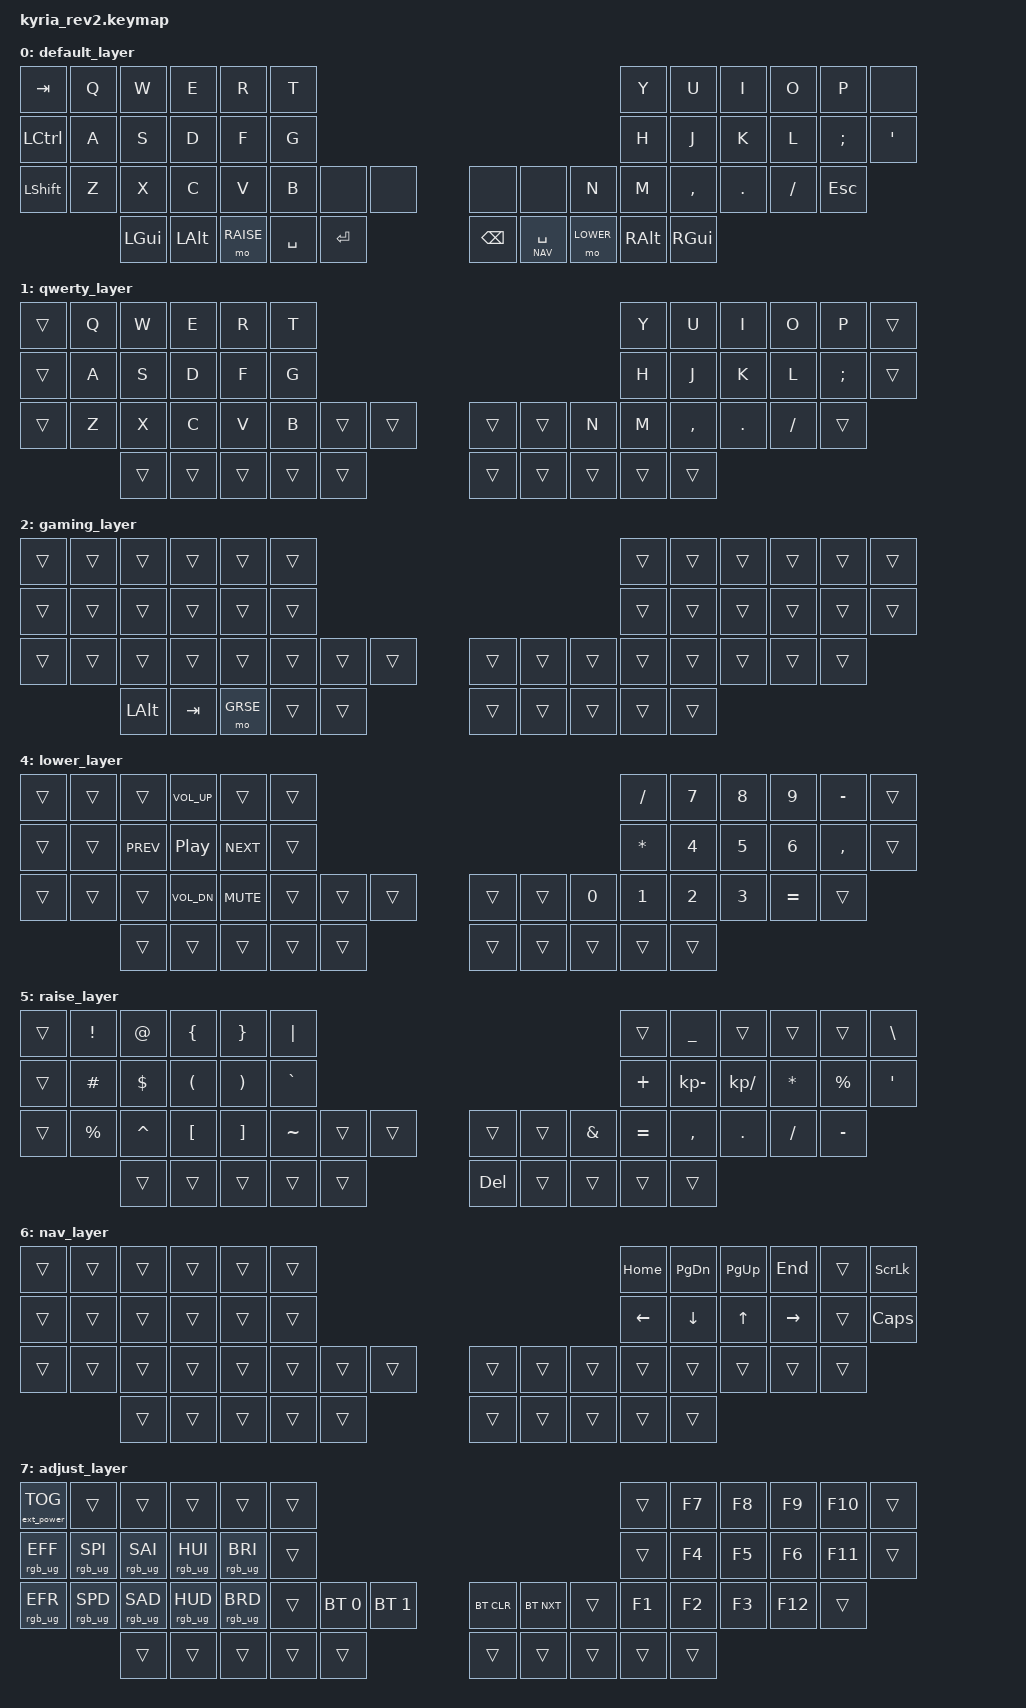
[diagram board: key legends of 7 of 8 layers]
/*
 * Copyright (c) 2020 The ZMK Contributors
 *
 * SPDX-License-Identifier: MIT
 */

#include <behaviors.dtsi>
#include <dt-bindings/zmk/bt.h>
#include <dt-bindings/zmk/keys.h>
/*
 * Temporarily here because nice nano v2 spi is not defined on ZMk Yet
 * Source: https://github.com/zmkfirmware/zmk/blob/main/app/boards/shields/reviung41/boards/nice_nano.overlay
 * GitHub Issue: https://github.com/zmkfirmware/zmk/issues/885
 */


#define QWERTY 0
#define QWERTY2  1
#define GAME    2
#define GRSE    3 // A special raise layer for main-half gaming.
#define LOWER   4
#define RAISE   5
#define NAV     6
#define ADJUST  7

/ {
    conditional_layers {
        compatible = "zmk,conditional-layers";
        tri_layer_1 {
            if-layers = <RAISE LOWER>;
            then-layer = <ADJUST>;
        };

		// Multiple conditional layers targeting the same then-layer is currently bugged.
		// https://github.com/zmkfirmware/zmk/pull/1084
		//tri_layer_2 {
        //    if-layers = <GRSE LOWER>;
        //    then-layer = <ADJUST>;
        //};
    };
};

/ {
    chosen {
      zmk,battery = &vbatt;
    };

    vbatt: vbatt {
        compatible = "zmk,battery-nrf-vddh";
        label = "VBATT";
    };
}

/ {
	keymap {
		compatible = "zmk,keymap";

		default_layer {
// ---------------------------------------------------------------------------------------------------------------------------------
// |  TAB  |  Q   |  W   |  E   |  R   |  T   |                                       |   Y   |   U   |   I   |   O   |   P   |   ENC   |
// |  CTRL |  A   |  S   |  D   |  F   |  G   |                                       |   H   |   J   |   K   |   L   |   ;   |   '   |
// | SHIFT |  Z   |  X   |  C   |  V   |  B   |       |      |         |      | _____ |   N   |   M   |   ,   |   .   |   /   | ESC   |
//                       | GUI  | ALT  | RSE  | SPACE | RET  |         | BSPC | SPACE |  LWR  | R-ALT |  GUI  |
//                                                                              /NAV
			bindings = <
	&kp TAB   &kp Q &kp W &kp E &kp R &kp T                                                      &kp Y     &kp U    &kp I     &kp O   &kp P     &none
	&kp LCTRL &kp A &kp S &kp D &kp F &kp G                                                      &kp H     &kp J    &kp K     &kp L   &kp SEMI    &kp SQT
	&kp LSHFT &kp Z &kp X &kp C &kp V &kp B    	 &none &none              &none &none        &kp N     &kp M    &kp COMMA &kp DOT &kp FSLH &kp ESC
	                &kp LGUI &kp LALT &mo RAISE &kp SPACE &kp RET        &kp BSPC  &lt NAV SPACE &mo LOWER &kp RALT &kp RGUI
			>;

			sensor-bindings = <&inc_dec_kp C_VOL_DN C_VOL_UP>;
		};

		qwerty_layer {
// ---------------------------------------------------------------------------------------------------------------------------------
// | ____ |   Q  |  W   |  E   |  R   |  T   |                                             |  Y   |  U   |  I   |  O   |  P   | ____ |
// | ____ |   A  |  S   |  D   |  F   |  G   |                                             |  H   |  J   |  K   |  L   |  ;   | ____ |
// | ____ |   Z  |  X   |  C   |  V   |  B   | ____ | ____ |                 | ____ | ____ |  N   |  M   |  ,   |  .   |  /   | ____ |
//                      | ____ | ____ | ____ | ____ | ____ |                 | ____ | ____ | ____ | ____ | ____ |
			bindings = <
		
	&trans  &kp Q &kp W &kp E  &kp R  &kp T                                    &kp Y  &kp U  &kp I     &kp O   &kp P    &trans
	&trans  &kp A &kp S &kp D  &kp F  &kp G                                    &kp H  &kp J  &kp K     &kp L   &kp SEMI &trans
	&trans  &kp Z &kp X &kp C  &kp V  &kp B  &trans &trans       &trans &trans &kp N  &kp M  &kp COMMA &kp DOT &kp FSLH &trans
	                    &trans &trans &trans &trans &trans       &trans &trans &trans &trans &trans
			>;

			sensor-bindings = <&inc_dec_kp C_VOL_DN C_VOL_UP>;
		};

		gaming_layer {
// --------------------------------------------------------------------------------------------------------------------------------
// | ____ | ____ | ____ | ____ | ____ | ____ |                                             | ____ | ____ | ____ | ____ | ____ | ____ |
// | ____ | ____ | ____ | ____ | ____ | ____ |                                             | ____ | ____ | ____ | ____ | ____ | ____ |
// | ____ | ____ | ____ | ____ | ____ | ____ | ____ | ____ |                 | ____ | ____ | ____ | ____ | ____ | ____ | ____ | ____ |
//                      | LALT | TAB  | GRSE | ____ | ____ |                 | ____ | ____ | ____ | ____ | ____ |
			bindings = <

	&trans &trans &trans &trans   &trans  &trans                                     &trans &trans &trans &trans &trans &trans
	&trans &trans &trans &trans   &trans  &trans                                     &trans &trans &trans &trans &trans &trans
	&trans &trans &trans &trans   &trans  &trans   &trans &trans       &trans &trans &trans &trans &trans &trans &trans &trans
	                     &kp LALT &kp TAB &mo GRSE &trans &trans       &trans &trans &trans &trans &trans
			>;

			sensor-bindings = <&inc_dec_kp C_VOL_DN C_VOL_UP>;
		};
		
		gaming_raise_layer {
// --------------------------------------------------------------------------------------------------------------------------------
// | F1   |  1   |  2   |  3   |  4   |  5   |                                             | ____ | ____ | ____ | ____ | ____ | ____ |
// | ____ | ____ | ____ | ____ | ____ | ____ |                                             | ____ | ____ | ____ | ____ | ____ | ____ |
// | ____ | ____ | ____ | ____ | ____ | ____ | ____ | ____ |                 | ____ | ____ | ____ | ____ | ____ | ____ | ____ | ____ |
//                      | ____ | ____ | ____ | ____ | ____ |                 | ____ | ____ | ____ | ____ | ____ |
			bindings = <

	&kp F1 &kp N1 &kp N2 &kp N3 &kp N4 &kp N5                                   &trans &trans &trans &trans &trans &trans
	&trans &trans &trans &trans &trans &trans                                   &trans &trans &trans &trans &trans &trans
	&trans &trans &trans &trans &trans &trans                                   &trans &trans &trans &trans &trans &trans
	                     &trans &trans &trans &trans &trans       &trans &trans &trans &trans &trans
			>;

			sensor-bindings = <&inc_dec_kp C_VOL_DN C_VOL_UP>;
		};
		

		lower_layer {
// ---------------------------------------------------------------------------------------------------------------------------------
// | ____ | ____ | ____ | VUP  | ____ | ____ |                                             | / ?  | 7 &  | 8 *  | 9 (  |  - _ | ____ |
// | ____ | ____ | PREV | PLAY | NEXT | ____ |                                             | *    | 4 $  | 5 %  | 6 ^  |  , < | ____ |
// | ____ | ____ | ____ | VDWN | MUTE | ____ | ____ | ____ |                 | ____ | ____ | 0 )  | 1 !  | 2 @  | 3 #  |  = + | ____ |
//                      | ____ | ____ | ____ | ____ | ____ |                 | ____ | ____ | ____ | ____ | ____ |
			bindings = <
	&trans  &trans &trans     &kp C_VOL_UP &trans     &trans                                        &kp FSLH &kp N7 &kp N8 &kp N9 &kp MINUS &trans
	&trans  &trans &kp C_PREV &kp C_PP     &kp C_NEXT &trans                                        &kp STAR &kp N4 &kp N5 &kp N6 &kp COMMA &trans
	&trans  &trans &trans     &kp C_VOL_DN &kp C_MUTE &trans     &trans &trans       &trans  &trans &kp N0   &kp N1 &kp N2 &kp N3 &kp EQUAL &trans
	                          &trans       &trans     &trans     &trans &trans       &trans  &trans &trans   &trans &trans
			>;

			sensor-bindings = <&inc_dec_kp C_VOL_DN C_VOL_UP>;
		};
	
		raise_layer {
// ---------------------------------------------------------------------------------------------------------------------------------
// | ____ |  !   |  @   |  {   |  }   |  |   |                                             | ____ |  _   | ____ | ____ | ____ |  \   |
// | ____ |  #   |  $   |  (   |  )   |  `   |                                             |  +   |  -   |  /   |  *   |  %   | ' "  |
// | ____ |  %   |  ^   |  [   |  ]   |  ~   | ____ | ____ |                 | ____ | ____ |  &   |  =   |  ,   |  .   | / ?  | - _  |
//                      | ____ | ____ | ____ | ____ | ____ |                 | ____ | ____ | ____ | ____ | ____ |
			bindings = <
	&trans  &kp EXCL  &kp AT    &kp LBRC &kp RBRC &kp PIPE                                     &trans     &kp UNDER    &trans       &trans     &trans    &kp BSLH
	&trans  &kp HASH  &kp DLLR  &kp LPAR &kp RPAR &kp GRAVE                                    &kp PLUS   &kp KP_MINUS &kp KP_SLASH &kp STAR   &kp PRCNT &kp SQT
	&trans  &kp PRCNT &kp CARET &kp LBKT &kp RBKT &kp TILDE &trans &trans       &trans  &trans &kp AMPS   &kp EQUAL    &kp COMMA    &kp DOT    &kp FSLH  &kp MINUS
	                            &trans   &trans   &trans    &trans &trans       &kp DEL &trans &trans     &trans       &trans
			>;

			sensor-bindings = <&inc_dec_kp C_VOL_DN C_VOL_UP>;
		};

		nav_layer {
// ---------------------------------------------------------------------------------------------------------------------------------
// | ____ | ____ | ____ | ____ | ____ | ____ |                                             | Home | PgDn | PgUp | End  | ____ | Slck |
// | ____ | ____ | ____ | ____ | ____ | ____ |                                             | Left | Down |  Up  | Right| ____ | Cclk |
// | ____ | ____ | ____ | ____ | ____ | ____ | ____ | ____ |                 | ____ | ____ | ____ | ____ | ____ | ____ | ____ | ____ |
//                      | ____ | ____ | ____ | ____ | ____ |                 | ____ | ____ | ____ | ____ | ____ |
			bindings = <
	&trans &trans &trans &trans &trans &trans                                    &kp HOME  &kp PG_DN &kp PG_UP &kp END   &trans &kp SLCK
	&trans &trans &trans &trans &trans &trans                                    &kp LEFT  &kp DOWN  &kp UP    &kp RIGHT &trans &kp CLCK
	&trans &trans &trans &trans &trans &trans &trans &trans       &trans &trans  &trans    &trans    &trans    &trans    &trans &trans
	                     &trans &trans &trans &trans &trans       &trans &trans  &trans    &trans    &trans
			>;

			sensor-bindings = <&inc_dec_kp C_VOL_DN C_VOL_UP>;
		};

		adjust_layer {
// ---------------------------------------------------------------------------------------------------------------------------------
// | VCC  | ____ | ____ | ____ | ____ | ____ |                                             | ____ |  F7  |  F8  |  F9  | F10  | ____ |
// | EFF  | SPI  | SAI  | HUI  | VAI  | ____ |                                             | ____ |  F4  |  F5  |  F6  | F11  | ____ |
// | EFR  | SPD  | SAD  | HUD  | VAD  | ____ | BLS0 | BLS1 |                 | BCLR | BNXT | ____ |  F1  |  F2  |  F3  | F12  | ____ |
//                      | ____ | ____ | ____ | ____ | ____ |                 | ____ | ____ | ____ | ____ | ____ |
			bindings = <
	&ext_power EP_TOG &trans           &trans            &trans          &trans          &trans                                                        &trans &kp F7 &kp F8 &kp F9 &kp F10 &trans
	&rgb_ug RGB_EFF   &rgb_ug RGB_SPI  &rgb_ug RGB_SAI   &rgb_ug RGB_HUI &rgb_ug RGB_BRI &trans                                                        &trans &kp F4 &kp F5 &kp F6 &kp F11 &trans
	&rgb_ug RGB_EFR   &rgb_ug RGB_SPD  &rgb_ug RGB_SAD   &rgb_ug RGB_HUD &rgb_ug RGB_BRD &trans &bt BT_SEL 0 &bt BT_SEL 1        &bt BT_CLR &bt BT_NXT &trans &kp F1 &kp F2 &kp F3 &kp F12 &trans
                                           &trans            &trans          &trans          &trans &trans       &trans              &trans     &trans     &trans &trans
			>;

			sensor-bindings = <&inc_dec_kp C_VOL_DN C_VOL_UP>;
		};
	};
};
